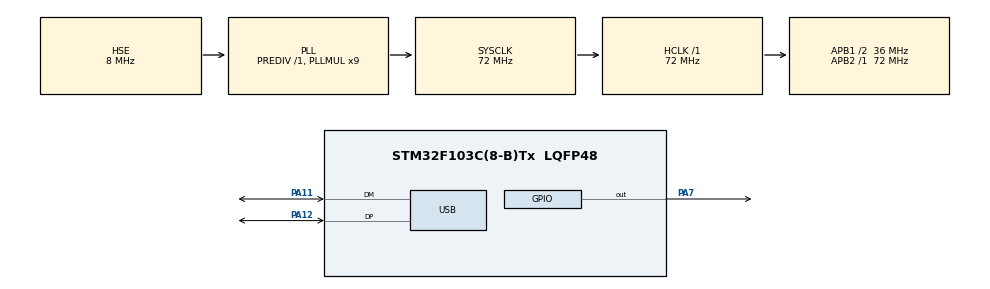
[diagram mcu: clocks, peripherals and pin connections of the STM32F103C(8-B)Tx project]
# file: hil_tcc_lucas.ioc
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Mcu.Family=STM32F1
Mcu.Name=STM32F103C(8-B)Tx
Mcu.Package=LQFP48
NVIC.PriorityGroup=NVIC_PRIORITYGROUP_4
NVIC.TIM2_IRQn=true\:0\:0\:false\:false\:true
NVIC.USB_LP_CAN1_RX0_IRQn=true\:0\:0\:false\:false\:true
PA11.Mode=Device
PA11.Signal=USB_DM
PA12.Mode=Device
PA12.Signal=USB_DP
PA13.Mode=Serial_Wire
PA13.Signal=SYS_JTMS-SWDIO
PA14.Mode=Serial_Wire
PA14.Signal=SYS_JTCK-SWCLK
PA7.Signal=GPIO_Output
PD0-OSC_IN.Mode=HSE-External-Oscillator
PD0-OSC_IN.Signal=RCC_OSC_IN
PD1-OSC_OUT.Mode=HSE-External-Oscillator
PD1-OSC_OUT.Signal=RCC_OSC_OUT
ProjectManager.HeapSize=0x200
ProjectManager.StackSize=0x400
ProjectManager.TargetToolchain=MDK-ARM V5
RCC.AHBFreq_Value=72000000
RCC.APB1CLKDivider=RCC_HCLK_DIV2
RCC.APB1Freq_Value=36000000
RCC.APB1TimFreq_Value=72000000
RCC.APB2Freq_Value=72000000
RCC.APB2TimFreq_Value=72000000
RCC.HCLKFreq_Value=72000000
RCC.HSIState=RCC_HSI_ON
RCC.PLLMUL=RCC_PLL_MUL9
RCC.SYSCLKFreq_VALUE=72000000
RCC.SYSCLKSource=RCC_SYSCLKSOURCE_PLLCLK
RCC.USBFreq_Value=48000000
RCC.USBPrescaler=RCC_USBCLKSOURCE_PLL_DIV1_5
TIM2.Period=99
TIM2.Prescaler=7200
USB_DEVICE.CLASS_NAME_FS=CDC
USB_DEVICE.USBD_HandleTypeDef=hUsbDeviceFS
USB_DEVICE.VirtualMode=Cdc
USB_DEVICE.VirtualModeFS=Cdc_FS
VP_TIM2_VS_ClockSourceINT.Mode=Internal
VP_USB_DEVICE_VS_USB_DEVICE_CDC_FS.Mode=CDC_FS
board=hil_tcc_lucas

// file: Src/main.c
/**
  ******************************************************************************
  * File Name          : main.c
  * Description        : Main program body
  ******************************************************************************
  *
  * COPYRIGHT(c) 2016 STMicroelectronics
  *
  * Redistribution and use in source and binary forms, with or without modification,
  * are permitted provided that the following conditions are met:
  *   1. Redistributions of source code must retain the above copyright notice,
  *      this list of conditions and the following disclaimer.
  *   2. Redistributions in binary form must reproduce the above copyright notice,
  *      this list of conditions and the following disclaimer in the documentation
  *      and/or other materials provided with the distribution.
  *   3. Neither the name of STMicroelectronics nor the names of its contributors
  *      may be used to endorse or promote products derived from this software
  *      without specific prior written permission.
  *
  * THIS SOFTWARE IS PROVIDED BY THE COPYRIGHT HOLDERS AND CONTRIBUTORS "AS IS"
  * AND ANY EXPRESS OR IMPLIED WARRANTIES, INCLUDING, BUT NOT LIMITED TO, THE
  * IMPLIED WARRANTIES OF MERCHANTABILITY AND FITNESS FOR A PARTICULAR PURPOSE ARE
  * DISCLAIMED. IN NO EVENT SHALL THE COPYRIGHT HOLDER OR CONTRIBUTORS BE LIABLE
  * FOR ANY DIRECT, INDIRECT, INCIDENTAL, SPECIAL, EXEMPLARY, OR CONSEQUENTIAL
  * DAMAGES (INCLUDING, BUT NOT LIMITED TO, PROCUREMENT OF SUBSTITUTE GOODS OR
  * SERVICES; LOSS OF USE, DATA, OR PROFITS; OR BUSINESS INTERRUPTION) HOWEVER
  * CAUSED AND ON ANY THEORY OF LIABILITY, WHETHER IN CONTRACT, STRICT LIABILITY,
  * OR TORT (INCLUDING NEGLIGENCE OR OTHERWISE) ARISING IN ANY WAY OUT OF THE USE
  * OF THIS SOFTWARE, EVEN IF ADVISED OF THE POSSIBILITY OF SUCH DAMAGE.
  *
  ******************************************************************************
  */
#include "stm32f1xx_hal.h"
#include "usb_device.h"

/* USER CODE BEGIN Includes */

#include <stddef.h>
#include <stdio.h>                     /* This ert_main.c example uses printf/fflush */
#include "sistema.h"                   /* Model's header file */
#include "rtwtypes.h"

//(INCLUIR)
#include "hil_lib.h"

/* USER CODE END Includes */

TIM_HandleTypeDef htim2;

/* USER CODE BEGIN PV */
/* Private variables ---------------------------------------------------------*/

/* USER CODE END PV */

void SystemClock_Config(void);
static void MX_GPIO_Init(void);
static void MX_TIM2_Init(void);

/* USER CODE BEGIN PFP */
/* Private function prototypes -----------------------------------------------*/

/* USER CODE END PFP */

int main(void)
{

  /* MCU Configuration----------------------------------------------------------*/

  /* Reset of all peripherals, Initializes the Flash interface and the Systick. */
  HAL_Init();

  /* Configure the system clock */
  SystemClock_Config();

  /* Initialize all configured peripherals */
  MX_GPIO_Init();
  MX_TIM2_Init();
  MX_USB_DEVICE_Init();

  /* USER CODE BEGIN 2 */

	//(CONTROLE)
	/* Initialize model */
  sistema_initialize();

  /* USER CODE END 2 */

  /* Infinite loop */
  /* USER CODE BEGIN WHILE */
  while (1)
  {
		HIL_Read();

  /* USER CODE END WHILE */

  }

}

/** System Clock Configuration
*/
void SystemClock_Config(void)
{

  RCC_OscInitTypeDef RCC_OscInitStruct;
  RCC_ClkInitTypeDef RCC_ClkInitStruct;
  RCC_PeriphCLKInitTypeDef PeriphClkInit;

  RCC_OscInitStruct.OscillatorType = RCC_OSCILLATORTYPE_HSE;
  RCC_OscInitStruct.HSEState = RCC_HSE_ON;
  RCC_OscInitStruct.HSEPredivValue = RCC_HSE_PREDIV_DIV1;
  RCC_OscInitStruct.PLL.PLLState = RCC_PLL_ON;
  RCC_OscInitStruct.PLL.PLLSource = RCC_PLLSOURCE_HSE;
  RCC_OscInitStruct.PLL.PLLMUL = RCC_PLL_MUL9;
  HAL_RCC_OscConfig(&RCC_OscInitStruct);

  RCC_ClkInitStruct.ClockType = RCC_CLOCKTYPE_HCLK|RCC_CLOCKTYPE_SYSCLK
                              |RCC_CLOCKTYPE_PCLK1|RCC_CLOCKTYPE_PCLK2;
  RCC_ClkInitStruct.SYSCLKSource = RCC_SYSCLKSOURCE_PLLCLK;
  RCC_ClkInitStruct.AHBCLKDivider = RCC_SYSCLK_DIV1;
  RCC_ClkInitStruct.APB1CLKDivider = RCC_HCLK_DIV2;
  RCC_ClkInitStruct.APB2CLKDivider = RCC_HCLK_DIV1;
  HAL_RCC_ClockConfig(&RCC_ClkInitStruct, FLASH_LATENCY_2);

  PeriphClkInit.PeriphClockSelection = RCC_PERIPHCLK_USB;
  PeriphClkInit.UsbClockSelection = RCC_USBCLKSOURCE_PLL_DIV1_5;
  HAL_RCCEx_PeriphCLKConfig(&PeriphClkInit);

  HAL_SYSTICK_Config(HAL_RCC_GetHCLKFreq()/1000);

  HAL_SYSTICK_CLKSourceConfig(SYSTICK_CLKSOURCE_HCLK);

  /* SysTick_IRQn interrupt configuration */
  HAL_NVIC_SetPriority(SysTick_IRQn, 0, 0);
}

/* TIM2 init function */
void MX_TIM2_Init(void)
{

  TIM_ClockConfigTypeDef sClockSourceConfig;
  TIM_MasterConfigTypeDef sMasterConfig;

  htim2.Instance = TIM2;
  htim2.Init.Prescaler = 3200;
  htim2.Init.CounterMode = TIM_COUNTERMODE_UP;
  htim2.Init.Period = 99;
  htim2.Init.ClockDivision = TIM_CLOCKDIVISION_DIV1;
  HAL_TIM_Base_Init(&htim2);

  sClockSourceConfig.ClockSource = TIM_CLOCKSOURCE_INTERNAL;
  HAL_TIM_ConfigClockSource(&htim2, &sClockSourceConfig);

  sMasterConfig.MasterOutputTrigger = TIM_TRGO_RESET;
  sMasterConfig.MasterSlaveMode = TIM_MASTERSLAVEMODE_DISABLE;
  HAL_TIMEx_MasterConfigSynchronization(&htim2, &sMasterConfig);

}

/** Configure pins as
        * Analog
        * Input
        * Output
        * EVENT_OUT
        * EXTI
*/
void MX_GPIO_Init(void)
{

  GPIO_InitTypeDef GPIO_InitStruct;

  /* GPIO Ports Clock Enable */
  __HAL_RCC_GPIOD_CLK_ENABLE();
  __HAL_RCC_GPIOA_CLK_ENABLE();

  /*Configure GPIO pin Output Level */
  HAL_GPIO_WritePin(GPIOA, GPIO_PIN_9, GPIO_PIN_RESET);

  /*Configure GPIO pin : PA7 */
  GPIO_InitStruct.Pin = GPIO_PIN_9;
  GPIO_InitStruct.Mode = GPIO_MODE_OUTPUT_PP;
  GPIO_InitStruct.Speed = GPIO_SPEED_FREQ_HIGH;
  HAL_GPIO_Init(GPIOA, &GPIO_InitStruct);

}

/* USER CODE BEGIN 4 */

//(INCLUIR) ISR of timmer 2 - Active after x ns
void HAL_TIM_PeriodElapsedCallback(TIM_HandleTypeDef *htim)
{
	if( htim->Instance == TIM2 )
	{
		HAL_GPIO_TogglePin(GPIOA, GPIO_PIN_7);
	}
}

/* USER CODE END 4 */

/************************ (C) COPYRIGHT STMicroelectronics *****END OF FILE****/
